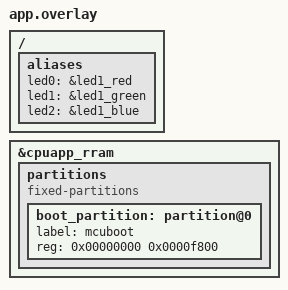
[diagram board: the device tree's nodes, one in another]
/*
 * Copyright (c) 2026 Nordic Semiconductor ASA
 *
 * SPDX-License-Identifier: LicenseRef-Nordic-5-Clause
 */

/ {
	aliases {
		led0 = &led1_red;
		led1 = &led1_green;
		led2 = &led1_blue;
	};
};

/* Shrink the MCUboot partition so FPROTECT can cover it on this SoC. */
/delete-node/ &boot_partition;

&cpuapp_rram {
	partitions {
		compatible = "fixed-partitions";
		#address-cells = <1>;
		#size-cells = <1>;

		boot_partition: partition@0 {
			label = "mcuboot";
			reg = <0x00000000 0x0000f800>;
		};
	};
};
